# AE822FA0E5597LS0_CM55_HP_View register map
Vendor: Alif Semiconductor; Series: E8; File version: 1.0
CPU: CM55 r1p0, selectable endian, MPU, FPU, double-precision FPU, DSP, VTOR, 8 interrupt priority bits, 1 SAU regions
Registers are 32-bit, read-write, reset 0x0 unless marked. A register's access mark holds for its fields unless they carry their own. Offsets are from the block's base; [hi:lo] are bit positions; 'fields as' and 'values as' point back to an identical list.

## CGU
Base 0x1A602000
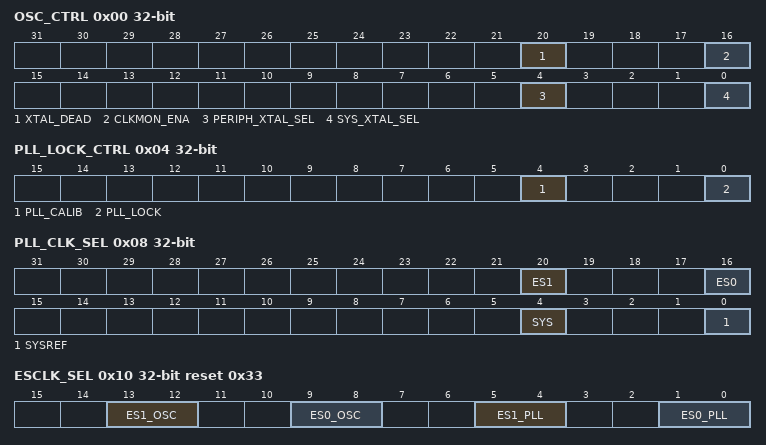
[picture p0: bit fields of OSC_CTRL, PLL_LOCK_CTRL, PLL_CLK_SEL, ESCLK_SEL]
0x00 OSC_CTRL — Oscillator Control Register
  [20] XTAL_DEAD ro — 38.4 MHz crystal-oscillator clock monitor status
    0=No crystal clock dead found; 1=Crystal clock dead detected
  [16] CLKMON_ENA — Enable 38.4 MHz crystal-oscillator clock monitor
    0=Disable clock monitor; 1=Enable clock monitor
  [4] PERIPH_XTAL_SEL — Select oscillator clock source for HFOSC_CLK
    0=Select 38.4 MHz (76.8 MHz / 2) ring-oscillator clock; 1=Select 38.4 MHz crystal-oscillator clock
  [0] SYS_XTAL_SEL — Select oscillator clock source for CPUPLL_CLK, SYSPLL_CLK, and SYST_REFCLK
    0=Select 76.8 MHz ring-oscillator clock; 1=Select 76.8 MHz (38.4 MHz x 2) crystal-oscillator clock
0x04 PLL_LOCK_CTRL — PLL Lock Control Register
  [4] PLL_CALIB ro — PLL calibration status
    0=PLL not in calibration; 1=PLL in calibration
  [0] PLL_LOCK — PLL lock control
    0=PLL not locked; 1=PLL locked
0x08 PLL_CLK_SEL — PLL Clock Select Register
  [20] ES1 — Select the source for RTSS_HE_CLK
    0=Select a value specified by the ESCLK_SEL[ES1_OSC] field; 1=Select a value specified by the ESCLK_SEL[ES1_PLL] field
  [16] ES0 — Select the source for RTSS_HP_CLK
    0=Select a value specified by the ESCLK_SEL[ES0_OSC] field; 1=Select a value specified by the ESCLK_SEL[ES0_PLL] field
  [4] SYS — Select the source for CPUPLL_CLK and SYSPLL_CLK
    0=Select oscillator clock source; 1=Select PLL clock source
  [0] SYSREF — Select the source for SYST_REFCLK
    0=Select oscillator clock source; 1=Select PLL clock source
0x10 ESCLK_SEL reset 0x33 — Clock Select Register for M55-HP and M55-HE
  [13:12] ES1_OSC — Select oscillator clock frequency for RTSS_HE_CLK
    0=Select 76.8 MHz ring-oscillator clock; 1=Select 38.4 MHz ring-oscillator clock; 2=Select 76.8 MHz crystal-oscillator clock; 3=Select 38.4 MHz crystal-oscillator clock
  [9:8] ES0_OSC — Select oscillator clock frequency for RTSS_HP_CLK
    values as ES1_OSC
  [5:4] ES1_PLL — Select PLL clock frequency for RTSS_HE_CLK
    0=Select 80 MHz PLL clock; 1=Select 80 MHz PLL clock; 2=Select 160 MHz PLL clock; 3=Select 160 MHz PLL clock
  [1:0] ES0_PLL — Select PLL clock frequency for RTSS_HP_CLK
    0=Select 100 MHz PLL clock; 1=Select 200 MHz PLL clock; 2=Select 400 MHz PLL clock; 3=Select 400 MHz PLL clock
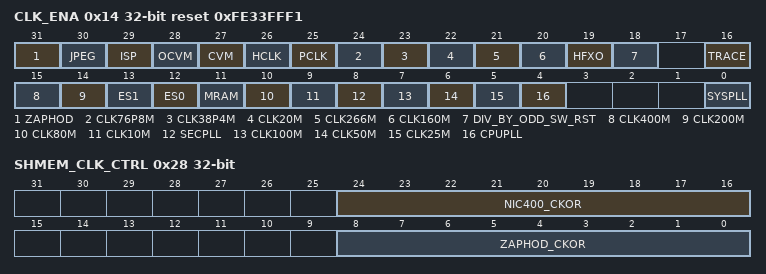
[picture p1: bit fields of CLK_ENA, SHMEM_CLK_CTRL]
0x14 CLK_ENA reset 0xFE33FFF1 — Clock Enable Register
  [31] ZAPHOD — Enable NPU-HG clock
    0=Disable clock; 1=Enable clock
  [30] JPEG — Enable JPEG clock
    0=Disable clock; 1=Enable clock
  [29] ISP — Enable ISP clock
    0=Disable clock; 1=Enable clock
  [28] OCVM — Enable SRAM1 clock
    0=Disable clock; 1=Enable clock
  [27] CVM — Enable SRAM0 clock
    0=Disable clock; 1=Enable clock
  [26] HCLK — Enable SYST_HCLK clock
    0=Disable clock; 1=Enable clock
  [25] PCLK — Enable SYST_PCLK clock
    0=Disable clock; 1=Enable clock
  [24] CLK76P8M — Enable 76M8_CLK clock
    0=Disable clock; 1=Enable clock
  [23] CLK38P4M — Enable HFOSC_CLK
    0=Disable clock; 1=Enable clock
  [22] CLK20M — Enable USB_CLK and 10M_CLK
    0=Disable clock; 1=Enable clock
  [21] CLK266M — Enable 266M_CLK
    0=Disable clock; 1=Enable clock
  [20] CLK160M — Enable PERIPH_CLK
    0=Disable clock; 1=Enable clock
  [19] HFXO — Enable clock to the HFXO_OUT pin
    0=Disable clock; 1=Enable clock
  [18] DIV_BY_ODD_SW_RST — DIV_BY_ODD SW reset
    0=Reset inactive; 1=Reset active
  [16] TRACE — Enable trace clock
    0=Disable clock; 1=Enable clock
  [15] CLK400M — Enable 400M_CLK
    0=Disable clock; 1=Enable clock
  [14] CLK200M — Enable 200 MHz PLL clock
    0=Disable clock; 1=Enable clock
  [13] ES1 — Enable RTSS_HE_CLK
    0=Disable clock; 1=Enable clock
  [12] ES0 — Enable RTSS_HP_CLK
    0=Disable clock; 1=Enable clock
  [11] MRAM — Enable MRAM clock
    0=Disable clock; 1=Enable clock
  [10] CLK80M — Enable 80 MHz PLL clock
    0=Disable clock; 1=Enable clock
  [9] CLK10M — Enable 20 MHz PLL clock
    0=Disable clock; 1=Enable clock
  [8] SECPLL — Enable SE PLL clock
    0=Disable clock; 1=Enable clock
  [7] CLK100M — Enable 100M_CLK
    0=Disable clock; 1=Enable clock
  [6] CLK50M — Enable internal 50 MHz ETH clock
    0=Disable clock; 1=Enable clock
  [5] CLK25M — Enable 25 MHz PLL clock
    0=Disable clock; 1=Enable clock
  [4] CPUPLL — Enable CPUPLL_CLK
    0=Disable clock; 1=Enable clock
  [0] SYSPLL — Enable SYSPLL_CLK
    0=Disable clock; 1=Enable clock
0x20 CGU_IRQ ro — CGU Interrupt Status Register
  [0] XTAL_DEAD read-clears — 38.4 MHz crystal-oscillator dead. Active high, read to clear. Note: The XTAL_DEAD interrupt is mapped to the Secure Enclave.
0x24 MISC_CLK_CTRL — Miscellaneous Clock Control Register
  [0] SEL_OSPI_CLK — HEXSPI clock source select
    0=400 MHz (SYST_ACLK); 1=266 MHz (266M_CLK from PLL). If this options is selected, bit CLK_ENA[CLK266M] should be set to enable the 266M_CLK.
0x28 SHMEM_CLK_CTRL — Shared Memory Clock Controllers Control Register
  [24:16] NIC400_CKOR — Shared Memory NIC clock override (bit 24)
    0=Dynamic clock (bits [23:16] specify the entry delay); 1=Forced clock
  [8:0] ZAPHOD_CKOR — NPU-HG clock override (bit 8)
    0=Dynamic clock (bits [7:0] specify the entry delay); 1=Forced clock
